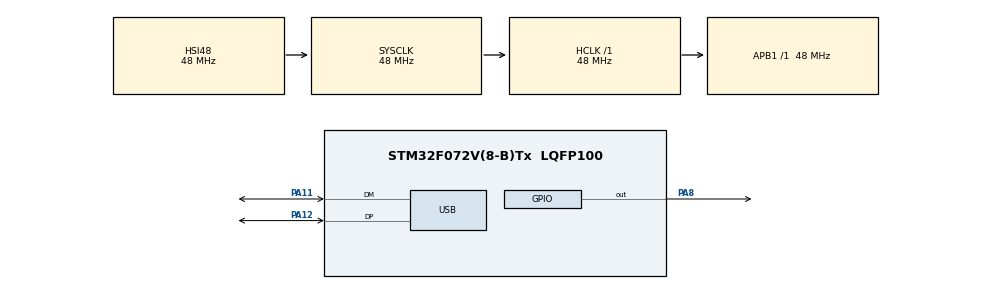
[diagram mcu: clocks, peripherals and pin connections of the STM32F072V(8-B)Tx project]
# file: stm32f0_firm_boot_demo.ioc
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Mcu.Family=STM32F0
Mcu.Name=STM32F072V(8-B)Tx
Mcu.Package=LQFP100
NVIC.USB_IRQn=true\:0\:0\:false\:false\:true\:false\:true\:true
PA11.Mode=Device
PA11.Signal=USB_DM
PA12.Mode=Device
PA12.Signal=USB_DP
PA13.Mode=Serial_Wire
PA13.Signal=SYS_SWDIO
PA14.Mode=Serial_Wire
PA14.Signal=SYS_SWCLK
PA8.Signal=GPIO_Output
PC14-OSC32_IN.Mode=LSE-External-Oscillator
PC14-OSC32_IN.Signal=RCC_OSC32_IN
PC15-OSC32_OUT.Mode=LSE-External-Oscillator
PC15-OSC32_OUT.Signal=RCC_OSC32_OUT
PF0-OSC_IN.Mode=HSE-External-Oscillator
PF0-OSC_IN.Signal=RCC_OSC_IN
PF1-OSC_OUT.Mode=HSE-External-Oscillator
PF1-OSC_OUT.Signal=RCC_OSC_OUT
ProjectManager.HeapSize=0x200
ProjectManager.StackSize=0x400
ProjectManager.TargetToolchain=STM32CubeIDE
RCC.AHBFreq_Value=48000000
RCC.APB1Freq_Value=48000000
RCC.APB1TimFreq_Value=48000000
RCC.HCLKFreq_Value=48000000
RCC.SYSCLKFreq_VALUE=48000000
RCC.SYSCLKSource=RCC_SYSCLKSOURCE_HSI48
USB_DEVICE.CLASS_NAME_FS=CDC
USB_DEVICE.VirtualMode=Cdc
USB_DEVICE.VirtualModeFS=Cdc_FS
VP_USB_DEVICE_VS_USB_DEVICE_CDC_FS.Mode=CDC_FS
board=custom

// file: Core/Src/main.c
/* USER CODE BEGIN Header */
/**
  ******************************************************************************
  * @file           : main.c
  * @brief          : Main program body
  ******************************************************************************
  * @attention
  *
  * Copyright (c) 2023 STMicroelectronics.
  * All rights reserved.
  *
  * This software is licensed under terms that can be found in the LICENSE file
  * in the root directory of this software component.
  * If no LICENSE file comes with this software, it is provided AS-IS.
  *
  ******************************************************************************
  */
/* USER CODE END Header */
#include "main.h"
#include "usb_device.h"

/* USER CODE BEGIN Includes */
#include <stdbool.h>
#include "flash.h"
/* USER CODE END Includes */

/* USER CODE BEGIN PD */
#define VECTOR_TABLE_SIZE (31 + 1 + 7 + 9)        // 31 positive vectors, 0 vector, and 7 negative vectors (and extra 9 i dont know why)
#define SYSCFG_CFGR1_MEM_MODE__MAIN_FLASH      0  // x0: Main Flash memory mapped at 0x0000 0000
#define SYSCFG_CFGR1_MEM_MODE__SYSTEM_FLASH    1  // 01: System Flash memory mapped at 0x0000 0000
#define SYSCFG_CFGR1_MEM_MODE__SRAM            3  // 11: Embedded SRAM mapped at 0x0000 0000
/* USER CODE END PD */

/* USER CODE BEGIN PV */
volatile uint32_t __attribute__((section(".ram_vector,\"aw\",%nobits @"))) ram_vector[VECTOR_TABLE_SIZE];
extern volatile uint32_t g_pfnVectors[VECTOR_TABLE_SIZE];
/* USER CODE END PV */

void SystemClock_Config(void);
static void MX_GPIO_Init(void);
/* USER CODE BEGIN PFP */
static uint8_t m_write_cfg_flash(uint64_t *cfg);
/* USER CODE END PFP */

/* USER CODE BEGIN 0 */
bool flagReset = false;
bool flagSendLoop = false;
uint8_t dataLoop[] = {0x18, 0x04};
/* USER CODE END 0 */

int main(void)
{
  /* USER CODE BEGIN 1 */
    RCC->APB2ENR |= RCC_APB2ENR_SYSCFGEN;  // early enable to ensure clock is up and running when it comes to usage

    for (uint32_t i = 0; i < VECTOR_TABLE_SIZE; i++) {//copy vector table
      ram_vector[i] = g_pfnVectors[i];
    }

    SYSCFG->CFGR1 = (SYSCFG->CFGR1 & ~SYSCFG_CFGR1_MEM_MODE) | (SYSCFG_CFGR1_MEM_MODE__SRAM * SYSCFG_CFGR1_MEM_MODE_0);  // remap 0x0000000 to RAM
  /* USER CODE END 1 */

  /* MCU Configuration--------------------------------------------------------*/

  /* Reset of all peripherals, Initializes the Flash interface and the Systick. */
  HAL_Init();

  /* Configure the system clock */
  SystemClock_Config();

  /* Initialize all configured peripherals */
  MX_GPIO_Init();
  MX_USB_DEVICE_Init();

  /* Infinite loop */
  while (1)
  {
	  if (flagSendLoop)
	  {
		  HAL_GPIO_TogglePin(GPIOA, GPIO_PIN_8);
		  CDC_Transmit_FS(dataLoop, 2);
		  HAL_Delay(1000);
	  }

	  if (flagReset)
	  {
		  uint64_t cfg_boot = 0xffffffffffffffb0;
		  m_write_cfg_flash(&cfg_boot);
		  HAL_NVIC_SystemReset();
	  }
  }
}

void SystemClock_Config(void)
{
  RCC_OscInitTypeDef RCC_OscInitStruct = {0};
  RCC_ClkInitTypeDef RCC_ClkInitStruct = {0};
  RCC_PeriphCLKInitTypeDef PeriphClkInit = {0};

  /** Initializes the RCC Oscillators according to the specified parameters
  * in the RCC_OscInitTypeDef structure.
  */
  RCC_OscInitStruct.OscillatorType = RCC_OSCILLATORTYPE_HSI48;
  RCC_OscInitStruct.HSI48State = RCC_HSI48_ON;
  RCC_OscInitStruct.PLL.PLLState = RCC_PLL_NONE;
  if (HAL_RCC_OscConfig(&RCC_OscInitStruct) != HAL_OK)
  {
    Error_Handler();
  }

  /** Initializes the CPU, AHB and APB buses clocks
  */
  RCC_ClkInitStruct.ClockType = RCC_CLOCKTYPE_HCLK|RCC_CLOCKTYPE_SYSCLK
                              |RCC_CLOCKTYPE_PCLK1;
  RCC_ClkInitStruct.SYSCLKSource = RCC_SYSCLKSOURCE_HSI48;
  RCC_ClkInitStruct.AHBCLKDivider = RCC_SYSCLK_DIV1;
  RCC_ClkInitStruct.APB1CLKDivider = RCC_HCLK_DIV1;

  if (HAL_RCC_ClockConfig(&RCC_ClkInitStruct, FLASH_LATENCY_1) != HAL_OK)
  {
    Error_Handler();
  }
  PeriphClkInit.PeriphClockSelection = RCC_PERIPHCLK_USB;
  PeriphClkInit.UsbClockSelection = RCC_USBCLKSOURCE_HSI48;

  if (HAL_RCCEx_PeriphCLKConfig(&PeriphClkInit) != HAL_OK)
  {
    Error_Handler();
  }
}

static void MX_GPIO_Init(void)
{
  GPIO_InitTypeDef GPIO_InitStruct = {0};

  /* GPIO Ports Clock Enable */
  __HAL_RCC_GPIOC_CLK_ENABLE();
  __HAL_RCC_GPIOF_CLK_ENABLE();
  __HAL_RCC_GPIOA_CLK_ENABLE();

  /*Configure GPIO pin Output Level */
  HAL_GPIO_WritePin(GPIOA, GPIO_PIN_8, GPIO_PIN_RESET);

  /*Configure GPIO pin : PA8 */
  GPIO_InitStruct.Pin = GPIO_PIN_8;
  GPIO_InitStruct.Mode = GPIO_MODE_OUTPUT_PP;
  GPIO_InitStruct.Pull = GPIO_NOPULL;
  GPIO_InitStruct.Speed = GPIO_SPEED_FREQ_LOW;
  HAL_GPIO_Init(GPIOA, &GPIO_InitStruct);

}

/* USER CODE BEGIN 4 */
static uint8_t m_write_cfg_flash(uint64_t *cfg)
{
  uint8_t status = true;
  uint32_t page = flash_get_page(CONFIG_START);

  if (FLASH_OK != flash_erase(page, 1))
  {
	status = false;
  }

  if (status == true)
  {
	if (FLASH_OK != flash_write(CONFIG_START, cfg, 1))
	{
	  status = false;
	}
  }

  return status;
}
/* USER CODE END 4 */

void Error_Handler(void)
{
  __disable_irq();
  while (1)
  {
  }
}
